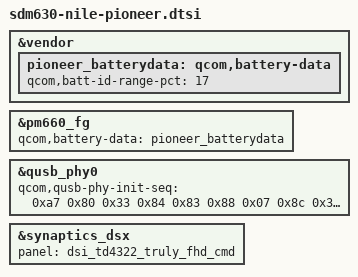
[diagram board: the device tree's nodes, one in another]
// SPDX-License-Identifier: GPL-2.0-only
/*
 * Copyright (c) 2017-2021, The Linux Foundation. All rights reserved.
 */

#include "sdm630-nile-common.dtsi"
#include "sdm630-nile-common-display.dtsi"
#include "sdm630-nile-pioneer-camera.dtsi"
#include "sdm630-nile-pioneer-display.dtsi"

&vendor {
	pioneer_batterydata: qcom,battery-data {
		qcom,batt-id-range-pct = <17>;
		#include "fg-gen3-batterydata-pioneer-send-4380mv.dtsi"
		#include "fg-gen3-batterydata-pioneer-tdk-4380mv.dtsi"
	};
};

&pm660_fg {
	qcom,battery-data = <&pioneer_batterydata>;
};

&qusb_phy0 {
	qcom,qusb-phy-init-seq = <0xa7 0x80
				  0x33 0x84
				  0x83 0x88
				  0x07 0x8c
				  0x30 0x08
				  0x79 0x0c
				  0x21 0x10
				  0x14 0x9c
				  0x9f 0x1c
				  0x00 0x18>;
};

&synaptics_dsx {
	panel = <&dsi_td4322_truly_fhd_cmd>;
};
